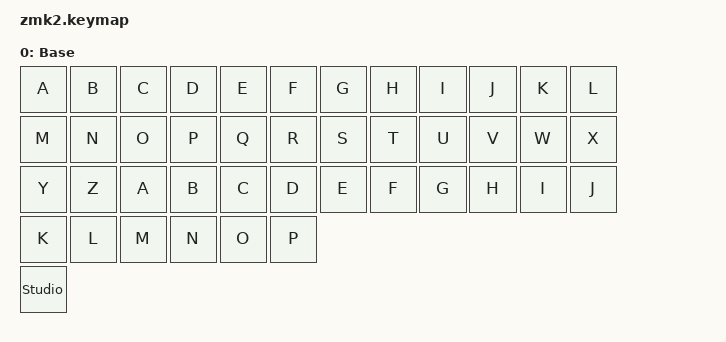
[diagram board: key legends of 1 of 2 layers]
#include <behaviors.dtsi>
#include <dt-bindings/zmk/keys.h>

/ {
    keymap {
        compatible = "zmk,keymap";

        default_layer {
            display-name = "Base";
            bindings = <
                &kp A &kp B &kp C &kp D &kp E &kp F &kp G &kp H &kp I &kp J &kp K &kp L
                &kp M &kp N &kp O &kp P &kp Q &kp R &kp S &kp T &kp U &kp V &kp W &kp X
                &kp Y &kp Z &kp A &kp B &kp C &kp D &kp E &kp F &kp G &kp H &kp I &kp J
                &kp K &kp L &kp M &kp N &kp O &kp P
                &studio_unlock
            >;
        };

        // Minimalus antras sluoksnis, kad Studio pamatytų
       layer_1 {
    display-name = "Layer 1";
    bindings = <
        &trans &trans &trans &trans &trans &trans &trans &trans &trans &trans &trans &trans
        &trans &trans &trans &trans &trans &trans &trans &trans &trans &trans &trans &trans
        &trans &trans &trans &trans &trans &trans &trans &trans &trans &trans &trans &trans
        &trans &trans &trans &trans &trans &trans
    >;
};
    };
};
